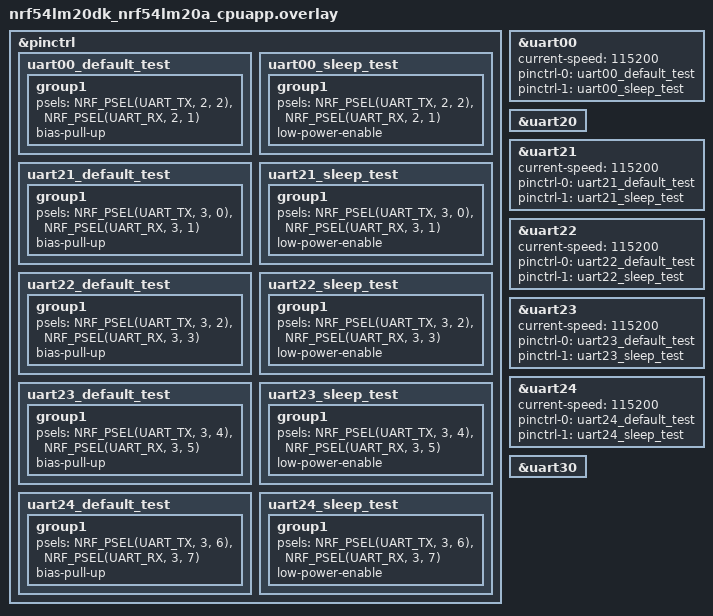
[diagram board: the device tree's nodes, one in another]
/*
 * Copyright (c) 2025 Nordic Semiconductor ASA
 *
 * SPDX-License-Identifier: LicenseRef-Nordic-5-Clause
 */

&pinctrl {
	uart00_default_test: uart00_default_test {
		group1 {
			psels = <NRF_PSEL(UART_TX, 2, 2)>,
				<NRF_PSEL(UART_RX, 2, 1)>;
			bias-pull-up;
		};
	};

	uart00_sleep_test: uart00_sleep_test {
		group1 {
			psels = <NRF_PSEL(UART_TX, 2, 2)>,
				<NRF_PSEL(UART_RX, 2, 1)>;
			low-power-enable;
		};
	};

	/* Use default configuration for uart20 */

	uart21_default_test: uart21_default_test {
		group1 {
			psels = <NRF_PSEL(UART_TX, 3, 0)>,
				<NRF_PSEL(UART_RX, 3, 1)>;
			bias-pull-up;
		};
	};

	uart21_sleep_test: uart21_sleep_test {
		group1 {
			psels = <NRF_PSEL(UART_TX, 3, 0)>,
				<NRF_PSEL(UART_RX, 3, 1)>;
			low-power-enable;
		};
	};

	uart22_default_test: uart22_default_test {
		group1 {
			psels = <NRF_PSEL(UART_TX, 3, 2)>,
				<NRF_PSEL(UART_RX, 3, 3)>;
			bias-pull-up;
		};
	};

	uart22_sleep_test: uart22_sleep_test {
		group1 {
			psels = <NRF_PSEL(UART_TX, 3, 2)>,
				<NRF_PSEL(UART_RX, 3, 3)>;
			low-power-enable;
		};
	};

	uart23_default_test: uart23_default_test {
		group1 {
			psels = <NRF_PSEL(UART_TX, 3, 4)>,
				<NRF_PSEL(UART_RX, 3, 5)>;
			bias-pull-up;
		};
	};

	uart23_sleep_test: uart23_sleep_test {
		group1 {
			psels = <NRF_PSEL(UART_TX, 3, 4)>,
				<NRF_PSEL(UART_RX, 3, 5)>;
			low-power-enable;
		};
	};

	uart24_default_test: uart24_default_test {
		group1 {
			psels = <NRF_PSEL(UART_TX, 3, 6)>,
				<NRF_PSEL(UART_RX, 3, 7)>;
			bias-pull-up;
		};
	};

	uart24_sleep_test: uart24_sleep_test {
		group1 {
			psels = <NRF_PSEL(UART_TX, 3, 6)>,
				<NRF_PSEL(UART_RX, 3, 7)>;
			low-power-enable;
		};
	};

	/* Use default configuration for uart30 */
};

&uart00 {
	status = "okay";
	current-speed = <115200>;
	pinctrl-0 = <&uart00_default_test>;
	pinctrl-1 = <&uart00_sleep_test>;
	pinctrl-names = "default", "sleep";
};

&uart20 {
	status = "okay";
};

&uart21 {
	status = "okay";
	current-speed = <115200>;
	pinctrl-0 = <&uart21_default_test>;
	pinctrl-1 = <&uart21_sleep_test>;
	pinctrl-names = "default", "sleep";
};

&uart22 {
	status = "okay";
	current-speed = <115200>;
	pinctrl-0 = <&uart22_default_test>;
	pinctrl-1 = <&uart22_sleep_test>;
	pinctrl-names = "default", "sleep";
};

&uart23 {
	status = "okay";
	current-speed = <115200>;
	pinctrl-0 = <&uart23_default_test>;
	pinctrl-1 = <&uart23_sleep_test>;
	pinctrl-names = "default", "sleep";
};

&uart24 {
	status = "okay";
	current-speed = <115200>;
	pinctrl-0 = <&uart24_default_test>;
	pinctrl-1 = <&uart24_sleep_test>;
	pinctrl-names = "default", "sleep";
};

&uart30 {
	status = "okay";
};
